# Generic_ARMv8MMainline register map
Vendor: ARM Ltd.; Series: ARMv8-M Mainline architecture (Cortex-M33 / Cortex-M35P / Cortex-M55 / Cortex-M85); File version: 1.0
CPU: CM33 r0p0, little endian, no MPU, no FPU, VTOR, 3 interrupt priority bits
Registers are 32-bit, read-write, reset 0x0 unless marked. A register's access mark holds for its fields unless they carry their own. Offsets are from the block's base; [hi:lo] are bit positions; {n}, {i} and the like mark numbered series; 'fields as' and 'values as' point back to an identical list.

## NVIC — Nested Vectored Interrupt Controller. ARMv8-M packs interrupt state into 16 banks of 32 bits each (ISER/ICER/ISPR/ICPR/IABR/ITNS) plus 124 32-bit IPR words, covering the full architectural maximum of 496 external interrupts (verified against CMSIS_6 core_cm23.h/core_cm33.h: IPR is a 496-byte array, i.e. 124 words of 4 packed 8-bit priorities each -- same total on both profiles). ITNS (Interrupt Target Non-Secure) is new versus ARMv6-M/ARMv7-M: one bit per interrupt selecting whether it targets the Secure or the Non-secure state; Secure-only access, and RAZ/WI when the Security Extension is not implemented. Mainline additionally has STIR, at the same offset as on ARMv7-M.
Base 0xE000E100
{0x0+4i} ISER{i} (i=0..15) — Interrupt Set-Enable Register
  [31:0] BITS
{0x80+4i} ICER{i} (i=0..15) — Interrupt Clear-Enable Register
  [31:0] BITS
{0x100+4i} ISPR{i} (i=0..15) — Interrupt Set-Pending Register
  [31:0] BITS
{0x180+4i} ICPR{i} (i=0..15) — Interrupt Clear-Pending Register
  [31:0] BITS
{0x200+4i} IABR{i} (i=0..15) ro — Interrupt Active Bit Register
  [31:0] BITS
{0x280+4i} ITNS{i} (i=0..15) — Interrupt Target Non-Secure Register -- Security Extension only, Secure-accessible
  [31:0] BITS
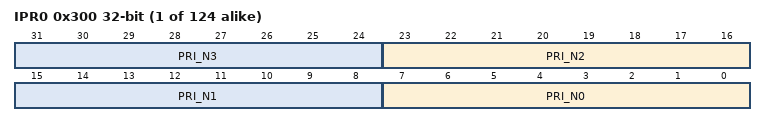
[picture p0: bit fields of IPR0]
{0x300+4i} IPR{i} (i=0..123) — Interrupt Priority Registers 0-123 (cover IRQ0..IRQ495)
  [8n+7:8n] PRI_N{n} (n=0..3) — Priority, byte offset {n}
0xE00 STIR wo — Software Trigger Interrupt Register. Only usable if SCB->CCR.USERSETMPEND allows unprivileged access and the device implements this register.
  [8:0] INTID — Interrupt ID of the interrupt to trigger, 0-495

## MPU — Memory Protection Unit -- OPTIONAL on ARMv8-M Mainline (__MPU_PRESENT). Region format changed from ARMv7-M's RBAR/RASR (base + size-encoded) to RBAR/RLAR (base + limit), and gained MAIR0/MAIR1 memory-attribute indirection registers (verified against CMSIS_6 core_cm23.h/core_cm33.h). Includes 3 alias RBAR/RLAR pairs, same as ARMv7-M (MPU_TYPE_RALIASES=4). RLAR.PXN (Privileged eXecute Never, bit 4) is Mainline-only -- absent from Baseline's RLAR entirely, not just RAZ/WI.
Base 0xE000ED90
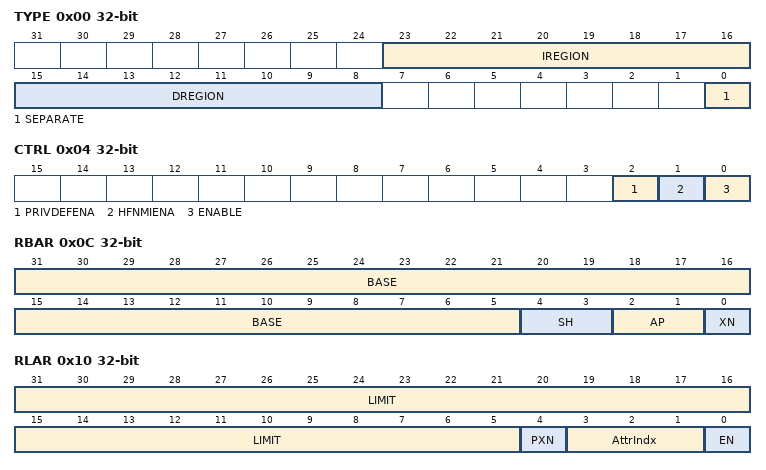
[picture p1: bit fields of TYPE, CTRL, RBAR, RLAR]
0x00 TYPE ro — MPU Type Register
  [23:16] IREGION, [15:8] DREGION, [0] SEPARATE
0x04 CTRL — MPU Control Register
  [2] PRIVDEFENA, [1] HFNMIENA, [0] ENABLE
0x08 RNR — MPU Region Number Register
  [7:0] REGION
0x0C RBAR — MPU Region Base Address Register
  [31:5] BASE — Base address, 32-byte aligned
  [4:3] SH — Shareability
  [2:1] AP — Access permissions
  [0] XN — Execute-never
0x10 RLAR — MPU Region Limit Address Register
  [31:5] LIMIT — Limit address, 32-byte aligned
  [4] PXN — Privileged eXecute Never -- new in CMSIS_6, Mainline only
  [3:1] AttrIndx — MAIR index
  [0] EN — Region enable
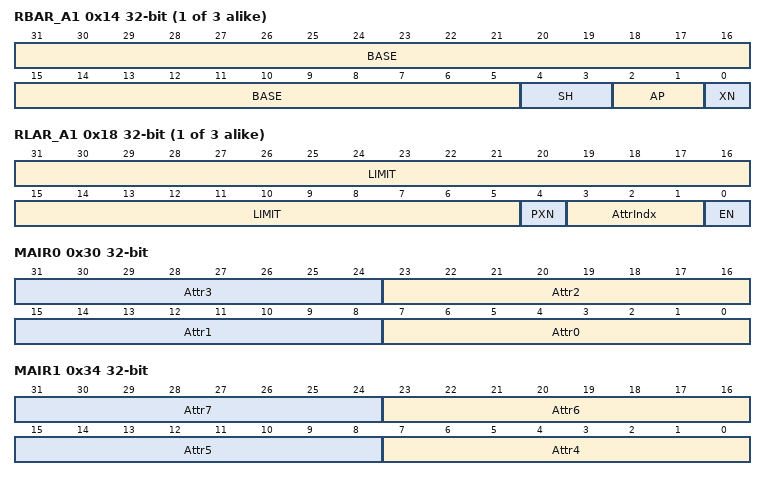
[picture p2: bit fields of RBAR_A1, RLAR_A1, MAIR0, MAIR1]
{0xC+8i} RBAR_A{i} (i=1..3) — MPU Region Base Address Register alias
  fields as RBAR
{0x10+8i} RLAR_A{i} (i=1..3) — MPU Region Limit Address Register alias
  fields as RLAR
0x30 MAIR0 — MPU Memory Attribute Indirection Register 0
  [8n+7:8n] Attr{n} (n=0..3)
0x34 MAIR1 — MPU Memory Attribute Indirection Register 1
  [8n-25:8n-32] Attr{n} (n=4..7)

## SAU — Security Attribution Unit -- present only when the Security Extension (TrustZone) is implemented; absent entirely on a Non-secure-only/single-state part. RNR/RBAR/RLAR are further optional within that: only present when __SAUREGION_PRESENT=1, i.e. the implementation has at least one programmable SAU region (a part can implement the Security Extension with the whole memory map fixed Secure/Non-secure by IDAU alone and no SAU regions at all). Verified against CMSIS_6 core_cm23.h/core_cm33.h (identical on both profiles). SFSR/SFAR are modeled once, under SCB, since SAU_Type and SCB_Type both expose the same physical registers at the same address on Mainline -- CMSIS_6 now says so explicitly (SAU_Type's own SFSR/SFAR are commented "deprecated: use SCB->SFSR"/"SCB->SFAR"); Baseline has neither (no SecureFault handler exists there).
Base 0xE000EDD0
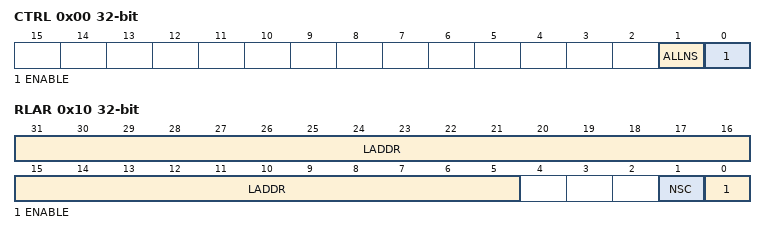
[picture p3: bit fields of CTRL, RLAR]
0x00 CTRL — SAU Control Register
  [1] ALLNS — All Non-secure -- forces the whole memory map Non-secure when SAU is disabled
  [0] ENABLE
0x04 TYPE ro — SAU Type Register
  [7:0] SREGION — Number of implemented SAU regions
0x08 RNR — SAU Region Number Register -- only present if __SAUREGION_PRESENT
  [7:0] REGION
0x0C RBAR — SAU Region Base Address Register -- only present if __SAUREGION_PRESENT
  [31:5] BADDR — Base address, 32-byte aligned
0x10 RLAR — SAU Region Limit Address Register -- only present if __SAUREGION_PRESENT
  [31:5] LADDR — Limit address, 32-byte aligned
  [1] NSC — Non-secure Callable
  [0] ENABLE
